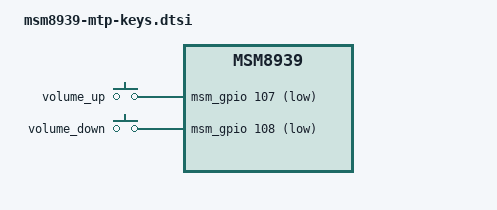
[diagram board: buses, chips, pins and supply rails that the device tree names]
/* Copyright (c) 2014, The Linux Foundation. All rights reserved.
 *
 * This program is free software; you can redistribute it and/or modify
 * it under the terms of the GNU General Public License version 2 and
 * only version 2 as published by the Free Software Foundation.
 *
 * This program is distributed in the hope that it will be useful,
 * but WITHOUT ANY WARRANTY; without even the implied warranty of
 * MERCHANTABILITY or FITNESS FOR A PARTICULAR PURPOSE.  See the
 * GNU General Public License for more details.
 */

&soc {
gpio_keys {
		compatible = "gpio-keys";
		input-name = "gpio-keys";
		pinctrl-names = "tlmm_gpio_key_active","tlmm_gpio_key_suspend";
		pinctrl-0 = <&gpio_key_active>;
		pinctrl-1 = <&gpio_key_suspend>;

		vol_up {
			label = "volume_up";
			gpios = <&msm_gpio 107 0x1>;
			linux,input-type = <1>;
			linux,code = <115>;
			gpio-key,wakeup;
			debounce-interval = <15>;
		};

		vol_down {
			label = "volume_down";
			gpios = <&msm_gpio 108 0x1>;
			linux,input-type = <1>;
			linux,code = <114>;
			gpio-key,wakeup;
			debounce-interval = <15>;
		};
	};
};


